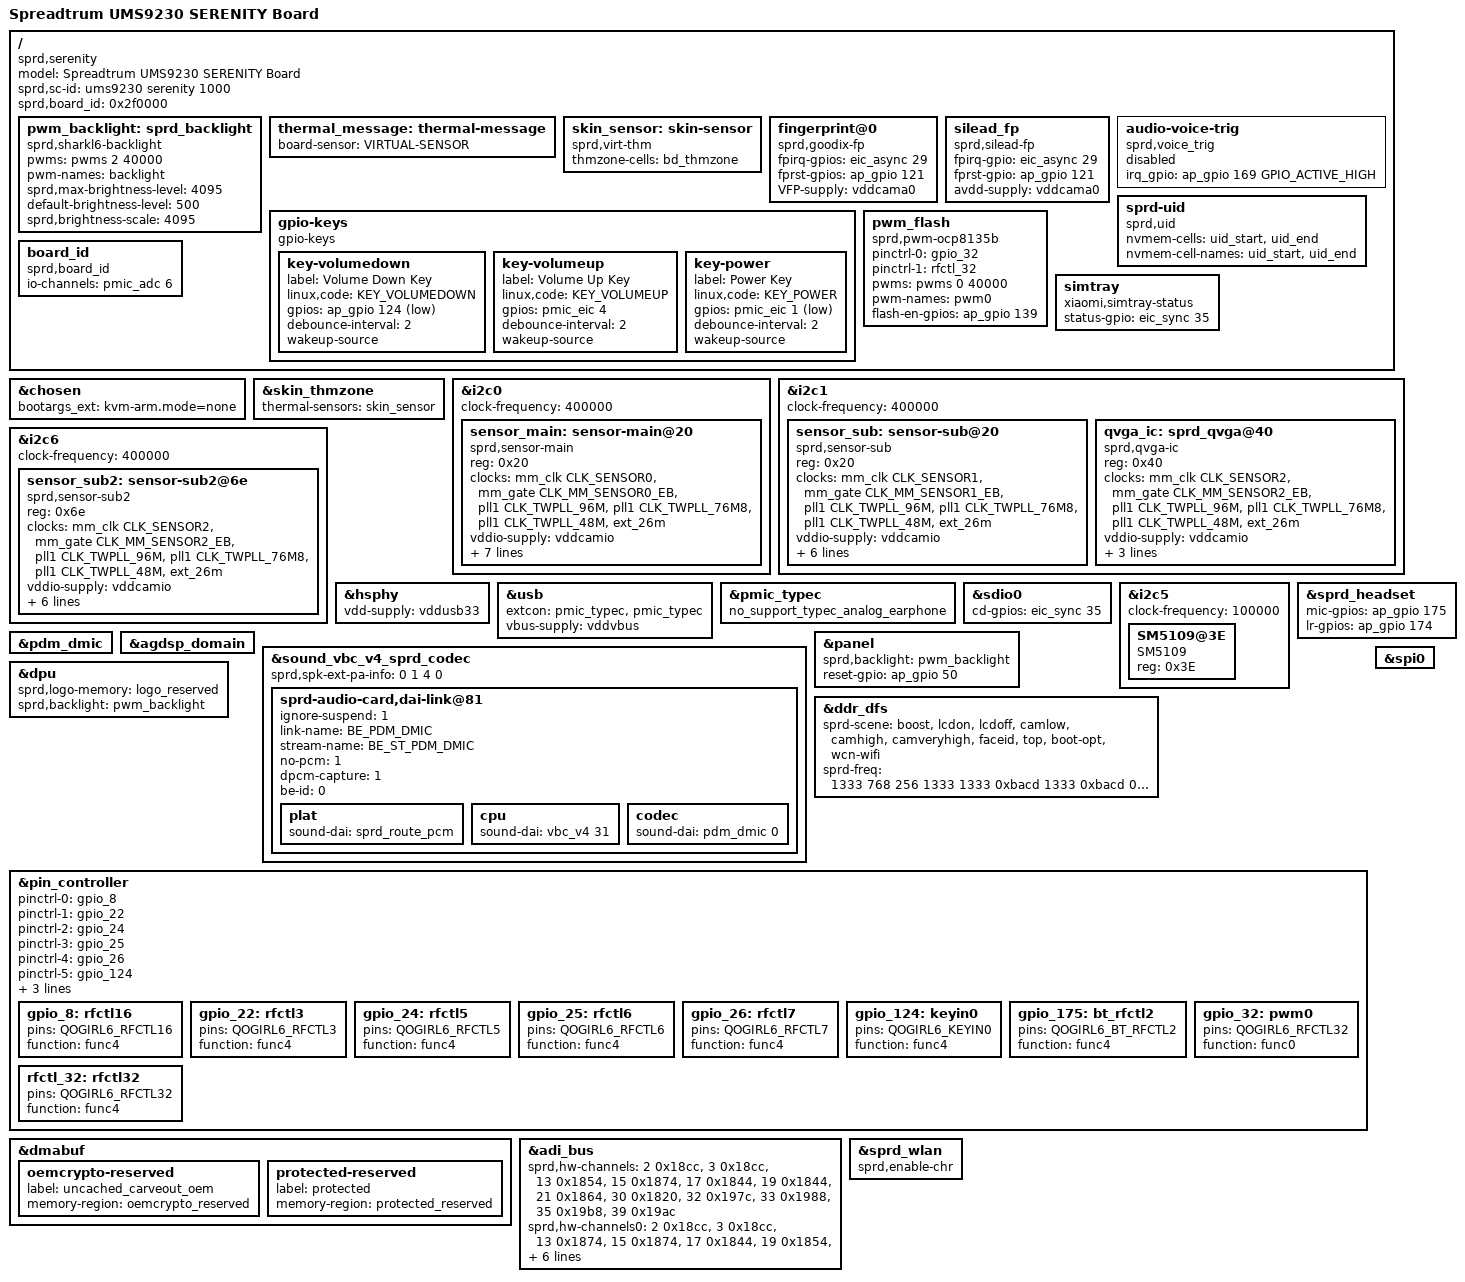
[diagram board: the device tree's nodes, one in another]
// SPDX-License-Identifier: GPL-2.0-only
/*
 * Spreadtrum UMS9230 Serenity board DTS overlay
 *
 * Xiaomi Redmi A5 / POCO C71 (serenity)
 * Unisoc T7250 (T615) / UMS9230
 *
 * Copyright (C) 2021, Unisoc Inc.
 * Ported from arctic-overlay.dts for serenity hardware.
 */

/dts-v1/;
/plugin/;
#include <dt-bindings/input/input.h>
#include <dt-bindings/gpio/gpio.h>
#include <dt-bindings/interrupt-controller/arm-gic.h>
#include <dt-bindings/clock/sprd,ums9230-clk.h>
#include <dt-bindings/mfd/sprd,sc2730-regs.h>
#include <dt-bindings/mfd/sprd,sc2730-mask.h>
#include <dt-bindings/usb/pd.h>
#include "lcd/lcd_g40396_truly_mipi_fhd.dtsi"
#include "lcd/lcd_nt36672e_truly_mipi_fhd_nodsc.dtsi"
#include "lcd/lcd_ft8725_boe_mipi_fhd_nodsc.dtsi"
#include "lcd/lcd_dummy_mipi.dtsi"
#include "touchscreen/spi3-touchscreen.dtsi"
#include "battery/serenity-overlay.dtsi"
#include "reserved-memory/serenity-overlay.dtsi"
#include "ums9230/wcn.dtsi"
#include "wcn/wcn_modules.h"
#include "wcn/chip/wcn-integrate-sharkl6-register.dtsi"

/ {

	model = "Spreadtrum UMS9230 SERENITY Board";

	compatible = "sprd,serenity";

	sprd,sc-id = "ums9230 serenity 1000";

	sprd,board_id = <0x2f0000>;

	fragment {
		target-path = "/";
		__overlay__ {
			pwm_backlight: sprd_backlight {
				compatible = "sprd,sharkl6-backlight";
				pwms = <&pwms 2 40000>;
				pwm-names = "backlight";
				sprd,max-brightness-level = <4095>;
				default-brightness-level = <500>;
				sprd,brightness-scale = <4095>;
			};
			thermal_message: thermal-message {
				board-sensor = "VIRTUAL-SENSOR";
			};

			skin_sensor: skin-sensor {
				compatible = "sprd,virt-thm";
				#thermal-sensor-cells = <0>;
				thmzone-cells = <&bd_thmzone>;
			};

			fingerprint@0 {
				status = "okay";
				compatible = "sprd,goodix-fp";
				fpirq-gpios = <&eic_async 29 0>;
				fprst-gpios = <&ap_gpio 121 0>;
				VFP-supply = <&vddcama0>;
			};
			silead_fp{
				status = "okay";
				compatible = "sprd,silead-fp";
				fpirq-gpio = <&eic_async 29 0>;
				fprst-gpio = <&ap_gpio 121 0>;
				avdd-supply = <&vddcama0>;
			};

			gpio-keys {
				compatible = "gpio-keys";

				key-volumedown {
					label = "Volume Down Key";
					linux,code = <KEY_VOLUMEDOWN>;
					gpios = <&ap_gpio 124 GPIO_ACTIVE_LOW>;
					debounce-interval = <2>;
					wakeup-source;
				};

				key-volumeup {
					label = "Volume Up Key";
					linux,code = <KEY_VOLUMEUP>;
					gpios = <&pmic_eic 4 GPIO_ACTIVE_HIGH>;
					debounce-interval = <2>;
					wakeup-source;
				};

				key-power {
					label = "Power Key";
					linux,code = <KEY_POWER>;
					gpios = <&pmic_eic 1 GPIO_ACTIVE_LOW>;
					debounce-interval = <2>;
					wakeup-source;
				};
			};

			audio-voice-trig {
				status = "disable";
				compatible = "sprd,voice_trig";
				irq_gpio = <&ap_gpio 169 GPIO_ACTIVE_HIGH>;
			};

			sprd-uid {
				compatible = "sprd,uid";
				nvmem-cells = <&uid_start>, <&uid_end>;
				nvmem-cell-names = "uid_start", "uid_end";
			};

			pwm_flash: pwm_flash {
				compatible = "sprd,pwm-ocp8135b";
				pinctrl-names = "gpio_32", "rfctl_32";
				pinctrl-0 = <&gpio_32>;
				pinctrl-1 = <&rfctl_32>;
				pwms = <&pwms 0 40000>;
				pwm-names = "pwm0";
				flash-en-gpios = <&ap_gpio 139 0>;
				#pwm-cells = <2>;
			};

			board_id: board_id {
				compatible = "sprd,board_id";
				io-channels = <&pmic_adc 6>;
				io-channel-names = "board_id-channel";
				status = "okay";
			};

			simtray {
				compatible = "xiaomi,simtray-status";
				status-gpio = <&eic_sync 35 GPIO_ACTIVE_HIGH>;
				status = "okay";
			};
		};
	};
};

&chosen {
	bootargs_ext = "kvm-arm.mode=none";
};

&skin_thmzone {
	thermal-sensors = <&skin_sensor>;
};

&i2c0 {
	status = "okay";
	clock-frequency = <400000>;
	#address-cells = <1>;
	#size-cells = <0>;

	sensor_main: sensor-main@20 {
		compatible = "sprd,sensor-main";
		reg = <0x20>;
		clock-names = "clk_src","sensor_eb",
			"clk_96m","clk_76m8",
			"clk_48m","clk_26m";
		clocks = <&mm_clk CLK_SENSOR0>,<&mm_gate CLK_MM_SENSOR0_EB>,
				<&pll1 CLK_TWPLL_96M>,<&pll1 CLK_TWPLL_76M8>,
				<&pll1 CLK_TWPLL_48M>,<&ext_26m>;
		vddio-supply = <&vddcamio>;
		vddcama-supply = <&vddldo1>;
		vddcamd-supply = <&vddcamd0>;
		vddcammot-supply = <&vddcammot>;
		reset-gpios = <&ap_gpio 44 0>;
		sprd,phyid = <2>;
		csi = <&csi0>;
		power-domains = <&mm_domain>;
	};
};

&i2c1 {
	status = "okay";
	clock-frequency = <400000>;
	#address-cells = <1>;
	#size-cells = <0>;
	sensor_sub: sensor-sub@20 {
		compatible = "sprd,sensor-sub";
		reg = <0x20>;
		clock-names = "clk_src","sensor_eb",
			"clk_96m","clk_76m8",
			"clk_48m","clk_26m";
		clocks = <&mm_clk CLK_SENSOR1>,<&mm_gate CLK_MM_SENSOR1_EB>,
				<&pll1 CLK_TWPLL_96M>,<&pll1 CLK_TWPLL_76M8>,
				<&pll1 CLK_TWPLL_48M>,<&ext_26m>;
		vddio-supply = <&vddcamio>;
		vddcama-supply = <&vddcama1>;
		vddcamd-supply = <&vddcamd1>;
		reset-gpios = <&ap_gpio 41 0>;
		sprd,phyid = <0>;
		csi = <&csi1>;
		power-domains = <&mm_domain>;
	};

	qvga_ic: sprd_qvga@40 {
		compatible = "sprd,qvga-ic";
		reg = <0x40>;
		clock-names = "clk_src","sensor_eb",
			"clk_96m","clk_76m8",
			"clk_48m","clk_26m";
		clocks = <&mm_clk CLK_SENSOR2>,<&mm_gate CLK_MM_SENSOR2_EB>,
				<&pll1 CLK_TWPLL_96M>,<&pll1 CLK_TWPLL_76M8>,
				<&pll1 CLK_TWPLL_48M>,<&ext_26m>;
		vddio-supply = <&vddcamio>;
		vddcama-supply = <&vddcama1>;
		reset-gpios = <&ap_gpio 45 0>;
		power-domains = <&mm_domain>;
	};
};

&i2c6 {
	status = "okay";
	clock-frequency = <400000>;
	#address-cells = <1>;
	#size-cells = <0>;

	sensor_sub2: sensor-sub2@6e {
		compatible = "sprd,sensor-sub2";
		reg = <0x6e>;
		clock-names = "clk_src","sensor_eb",
			"clk_96m","clk_76m8",
			"clk_48m","clk_26m";
		clocks = <&mm_clk CLK_SENSOR2>,<&mm_gate CLK_MM_SENSOR2_EB>,
			<&pll1 CLK_TWPLL_96M>,<&pll1 CLK_TWPLL_76M8>,
			<&pll1 CLK_TWPLL_48M>,<&ext_26m>;
		vddio-supply = <&vddcamio>;
		avdd-gpios = <&ap_gpio 130 0>;
		vddcamd-supply = <&vddcamd1>;
		vddcammot-supply = <&vddcammot>;
		reset-gpios = <&ap_gpio 114 0>;
		sprd,phyid = <3>;
		csi = <&csi2>;
	};
};

&hsphy {
	vdd-supply = <&vddusb33>;
	status = "okay";
};

&usb {
	extcon = <&pmic_typec>, <&pmic_typec>;
	vbus-supply = <&vddvbus>;
	status = "okay";
};

&pmic_typec {
	no_support_typec_analog_earphone;
	status = "okay";
};

&sdio0 {
	cd-gpios = <&eic_sync 35 GPIO_ACTIVE_HIGH>;
};

&i2c5 {
	status = "okay";
	clock-frequency = <100000>;
	SM5109@3E {
		compatible = "SM5109";
		reg = <0x3E>;
		status = "okay";
	};
};

&sprd_headset {
	status = "okay";
	mic-gpios = <&ap_gpio 175 GPIO_ACTIVE_HIGH>;
	lr-gpios = <&ap_gpio 174 GPIO_ACTIVE_HIGH>;
};

&pdm_dmic {
	status = "okay";
};

&agdsp_domain {
	status = "okay";
};

&sound_vbc_v4_sprd_codec {
	status = "okay";
	/* 63: pdm dmic */
	sprd-audio-card,dai-link@81 {
		ignore-suspend = <1>;
		link-name = "BE_PDM_DMIC";
		stream-name = "BE_ST_PDM_DMIC";
		no-pcm = <1>;
		dpcm-capture = <1>;
		be-id = <0>;
		plat {
			sound-dai = <&sprd_route_pcm>;
		};
		cpu {
			sound-dai = <&vbc_v4 31>;
		};
		codec {
			sound-dai = <&pdm_dmic 0>;
		};
	};
};

&panel {
	sprd,backlight = <&pwm_backlight>;
	reset-gpio = <&ap_gpio 50 GPIO_ACTIVE_HIGH>;
};

&dpu {
	sprd,logo-memory = <&logo_reserved>;
	sprd,backlight = <&pwm_backlight>;
};

&ddr_dfs {
	  sprd-scene = "boost", "lcdon", "lcdoff", "camlow",
			"camhigh", "camveryhigh", "faceid", "top", "boot-opt", "wcn-wifi";
	  sprd-freq = <1333 768 256 1333 1333 0xbacd 1333 0xbacd 0xbacd 1333>;
};

&pin_controller {
	pinctrl-names =
	/* rfctl16, rfctl3, rfctl5 */
	"gpio_8", "gpio_22", "gpio_24",
	/* rfctl6, rfctl7, keyin0 */
	"gpio_25", "gpio_26", "gpio_124",
	/* bt_rfctl2 */
	"gpio_175",
	/* pwm_flash gpio_32 */
	"gpio_32", "rfctl_32";
	pinctrl-0 = <&gpio_8>;
	pinctrl-1 = <&gpio_22>;
	pinctrl-2 = <&gpio_24>;
	pinctrl-3 = <&gpio_25>;
	pinctrl-4 = <&gpio_26>;
	pinctrl-5 = <&gpio_124>;
	pinctrl-6 = <&gpio_175>;
	pinctrl-7 = <&gpio_32>;
	pinctrl-8 = <&rfctl_32>;

	gpio_8: rfctl16 {
		pins = "QOGIRL6_RFCTL16";
		function = "func4";
	};

	gpio_22: rfctl3 {
		pins = "QOGIRL6_RFCTL3";
		function = "func4";
	};

	gpio_24: rfctl5 {
		pins = "QOGIRL6_RFCTL5";
		function = "func4";
	};

	gpio_25: rfctl6 {
		pins = "QOGIRL6_RFCTL6";
		function = "func4";
	};

	gpio_26: rfctl7 {
		pins = "QOGIRL6_RFCTL7";
		function = "func4";
	};

	gpio_124: keyin0 {
		pins = "QOGIRL6_KEYIN0";
		function = "func4";
	};

	gpio_175: bt_rfctl2 {
		pins = "QOGIRL6_BT_RFCTL2";
		function = "func4";
	};

	gpio_32: pwm0 {
		pins = "QOGIRL6_RFCTL32";
		function = "func0";
	};

	rfctl_32: rfctl32 {
		pins = "QOGIRL6_RFCTL32";
		function = "func4";
	};
};

&dmabuf {
	oemcrypto-reserved {
		label = "uncached_carveout_oem";
		memory-region = <&oemcrypto_reserved>;
	};

	protected-reserved {
		label = "protected";
		memory-region = <&protected_reserved>;
	};
};

&adi_bus {
	sprd,hw-channels = <2 0x18cc>, <3 0x18cc>, <13 0x1854>, <15 0x1874>,
			<17 0x1844>, <19 0x1844>, <21 0x1864>, <30 0x1820>,
			<32 0x197c>, <33 0x1988>, <35 0x19b8>, <39 0x19ac>;
	sprd,hw-channels0 = <2 0x18cc>, <3 0x18cc>, <13 0x1874>, <15 0x1874>,
			<17 0x1844>, <19 0x1854>, <21 0x1864>, <30 0x1820>,
			<32 0x197c>, <33 0x1988>, <35 0x19b8>, <39 0x19ac>;
	sprd,hw-channels1 = <2 0x18cc>, <3 0x18cc>, <13 0x1854>, <15 0x1874>,
			<17 0x1844>, <19 0x1844>, <21 0x1864>, <30 0x1820>,
			<32 0x197c>, <33 0x1988>, <35 0x19b8>, <39 0x19ac>;
};

&sprd_wlan {
	sprd,enable-chr;
};

&spi0 {
	/* used for fingerprint */
	status = "okay";
};

&sound_vbc_v4_sprd_codec {
	status = "okay";
	sprd,spk-ext-pa-info = <0 1 4 0>;
};
